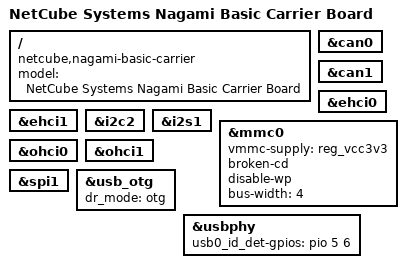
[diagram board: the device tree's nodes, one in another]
// SPDX-License-Identifier: (GPL-2.0+ OR MIT)
/*
 * Copyright (C) 2025 Lukas Schmid <lukas.schmid@netcube.li>
 */

/dts-v1/;
#include "sun8i-t113s-netcube-nagami.dtsi"

/ {
	model = "NetCube Systems Nagami Basic Carrier Board";
	compatible = "netcube,nagami-basic-carrier", "netcube,nagami",
		     "allwinner,sun8i-t113s";
};

&can0 {
	status = "okay";
};

&can1 {
	status = "okay";
};

&ehci0 {
	status = "okay";
};

&ehci1 {
	status = "okay";
};

&i2c2 {
	status = "okay";
};

&i2s1 {
	status = "okay";
};

&mmc0 {
	vmmc-supply = <&reg_vcc3v3>;
	broken-cd;
	disable-wp;
	bus-width = <4>;
	status = "okay";
};

&ohci0 {
	status = "okay";
};

&ohci1 {
	status = "okay";
};

&spi1 {
	status = "okay";
};

&usb_otg {
	dr_mode = "otg";
	status = "okay";
};

&usbphy {
	usb0_id_det-gpios = <&pio 5 6 GPIO_ACTIVE_HIGH>; /* PF6 */
	status = "okay";
};
